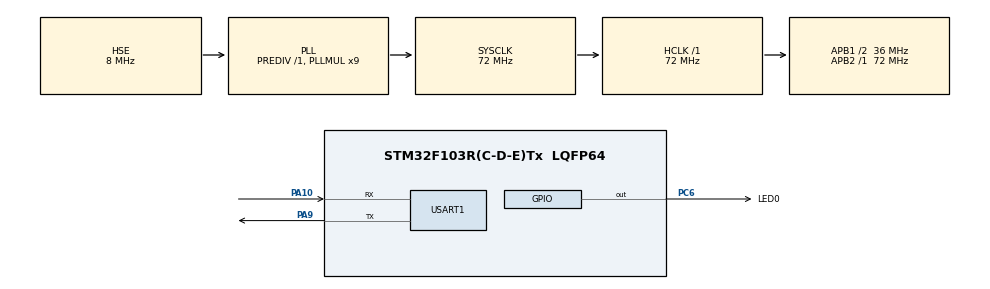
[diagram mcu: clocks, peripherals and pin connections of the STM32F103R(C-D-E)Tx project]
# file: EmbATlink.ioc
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Mcu.Family=STM32F1
Mcu.Name=STM32F103R(C-D-E)Tx
Mcu.Package=LQFP64
NVIC.PriorityGroup=NVIC_PRIORITYGROUP_4
NVIC.USART1_IRQn=true\:0\:0\:false\:false\:true\:true\:true\:true
PA10.Mode=Asynchronous
PA10.Signal=USART1_RX
PA13.Mode=Serial_Wire
PA13.Signal=SYS_JTMS-SWDIO
PA14.Mode=Serial_Wire
PA14.Signal=SYS_JTCK-SWCLK
PA9.Mode=Asynchronous
PA9.Signal=USART1_TX
PC6.GPIO_Label=LED0
PC6.Signal=GPIO_Output
PD0-OSC_IN.Mode=HSE-External-Oscillator
PD0-OSC_IN.Signal=RCC_OSC_IN
PD1-OSC_OUT.Mode=HSE-External-Oscillator
PD1-OSC_OUT.Signal=RCC_OSC_OUT
ProjectManager.HeapSize=0x200
ProjectManager.StackSize=0x400
ProjectManager.TargetToolchain=MDK-ARM V5.32
RCC.AHBFreq_Value=72000000
RCC.APB1CLKDivider=RCC_HCLK_DIV2
RCC.APB1Freq_Value=36000000
RCC.APB1TimFreq_Value=72000000
RCC.APB2Freq_Value=72000000
RCC.APB2TimFreq_Value=72000000
RCC.HCLKFreq_Value=72000000
RCC.PLLMUL=RCC_PLL_MUL9
RCC.PLLSourceVirtual=RCC_PLLSOURCE_HSE
RCC.SYSCLKFreq_VALUE=72000000
RCC.SYSCLKSource=RCC_SYSCLKSOURCE_PLLCLK
RCC.USBFreq_Value=72000000
USART1.VirtualMode=VM_ASYNC
board=custom

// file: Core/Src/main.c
/* USER CODE BEGIN Header */
/**
 ******************************************************************************
 * @file           : main.c
 * @brief          : Main program body
 ******************************************************************************
 * @attention
 *
 * Copyright (c) 2026 STMicroelectronics.
 * All rights reserved.
 *
 * This software is licensed under terms that can be found in the LICENSE file
 * in the root directory of this software component.
 * If no LICENSE file comes with this software, it is provided AS-IS.
 *
 ******************************************************************************
 */
/* USER CODE END Header */
#include "main.h"
#include "usart.h"
#include "gpio.h"

/* USER CODE BEGIN Includes */
#include <stdio.h>
#include <string.h>
#include "at_driver.h"
/* USER CODE END Includes */

void SystemClock_Config(void);

/* USER CODE BEGIN 0 */
int fputc(int ch, FILE *f)
{
  HAL_UART_Transmit(&huart1, (uint8_t *)&ch, 1, 0xFFFF);
  return ch;
}

/* USER CODE END 0 */

int main(void)
{

  /* MCU Configuration--------------------------------------------------------*/

  /* Reset of all peripherals, Initializes the Flash interface and the Systick. */
  HAL_Init();

  /* Configure the system clock */
  SystemClock_Config();

  /* Initialize all configured peripherals */
  MX_GPIO_Init();
  MX_USART1_UART_Init();
  /* USER CODE BEGIN 2 */

  HAL_GPIO_WritePin(LED0_GPIO_Port, LED0_Pin, GPIO_PIN_SET);
  at_init();

  char *recv_buffer = NULL;
  uint8_t ret;

  printf("===== AT Driver Send Start =====\r\n");

  ret = at_cmd_format_send_and_recv(0, &recv_buffer, AT, ""); // 发送AT指令,并接收返回的数据
  printf("ret:%d, recv: %s\r\n", ret, recv_buffer);           // 打印返回的数据

  ret = at_cmd_format_send_and_recv(0, &recv_buffer, ATE, "%d", 1); // 可变参数AT指令，变成：ATE1
  printf("ret:%d, recv: %s\r\n", ret, recv_buffer);                 // ATE配置接收为NULL，代表无需匹配接收数据，直接返回

  HAL_Delay(1000);

  at_clear_recv_buffer(0); // 清空接收缓冲区

  printf("===== AT Driver Recviev Start =====\r\n");

  /* USER CODE END 2 */

  /* Infinite loop */
  while (1)
  {

    /* USER CODE BEGIN 3 */

    // 监听 at_monitor_key_table 中定义的数据
    uint8_t monitor_idx = at_get_monitor_match_index(0);
    if (monitor_idx != 0xFF) // 匹配成功
    {
      char *recv_buffer = at_get_recv_buffer(0); // 获取接收到的数据

      printf("Event[%d]: %s\r\n", monitor_idx, recv_buffer); // 打印监听到的数据下标，和接收到的数据

      switch (monitor_idx) // 根据下标执行不同的操作
      {
      case SYS_LED0_ON:
        HAL_GPIO_WritePin(LED0_GPIO_Port, LED0_Pin, GPIO_PIN_RESET);
        break;
      case SYS_LED0_OFF:
        HAL_GPIO_WritePin(LED0_GPIO_Port, LED0_Pin, GPIO_PIN_SET);
        break;
      case SYS_LED0_TOGGLE:
        HAL_GPIO_TogglePin(LED0_GPIO_Port, LED0_Pin);
        break;
      default:
        break;
      }
      at_clear_recv_buffer(0); // 清空接收缓冲区
    }
    HAL_Delay(10);
  }
  /* USER CODE END 3 */
}

void SystemClock_Config(void)
{
  RCC_OscInitTypeDef RCC_OscInitStruct = {0};
  RCC_ClkInitTypeDef RCC_ClkInitStruct = {0};

  /** Initializes the RCC Oscillators according to the specified parameters
   * in the RCC_OscInitTypeDef structure.
   */
  RCC_OscInitStruct.OscillatorType = RCC_OSCILLATORTYPE_HSE;
  RCC_OscInitStruct.HSEState = RCC_HSE_ON;
  RCC_OscInitStruct.HSEPredivValue = RCC_HSE_PREDIV_DIV1;
  RCC_OscInitStruct.HSIState = RCC_HSI_ON;
  RCC_OscInitStruct.PLL.PLLState = RCC_PLL_ON;
  RCC_OscInitStruct.PLL.PLLSource = RCC_PLLSOURCE_HSE;
  RCC_OscInitStruct.PLL.PLLMUL = RCC_PLL_MUL9;
  if (HAL_RCC_OscConfig(&RCC_OscInitStruct) != HAL_OK)
  {
    Error_Handler();
  }

  /** Initializes the CPU, AHB and APB buses clocks
   */
  RCC_ClkInitStruct.ClockType = RCC_CLOCKTYPE_HCLK | RCC_CLOCKTYPE_SYSCLK | RCC_CLOCKTYPE_PCLK1 | RCC_CLOCKTYPE_PCLK2;
  RCC_ClkInitStruct.SYSCLKSource = RCC_SYSCLKSOURCE_PLLCLK;
  RCC_ClkInitStruct.AHBCLKDivider = RCC_SYSCLK_DIV1;
  RCC_ClkInitStruct.APB1CLKDivider = RCC_HCLK_DIV2;
  RCC_ClkInitStruct.APB2CLKDivider = RCC_HCLK_DIV1;

  if (HAL_RCC_ClockConfig(&RCC_ClkInitStruct, FLASH_LATENCY_2) != HAL_OK)
  {
    Error_Handler();
  }
}

void Error_Handler(void)
{
  __disable_irq();
  while (1)
  {
  }
}
